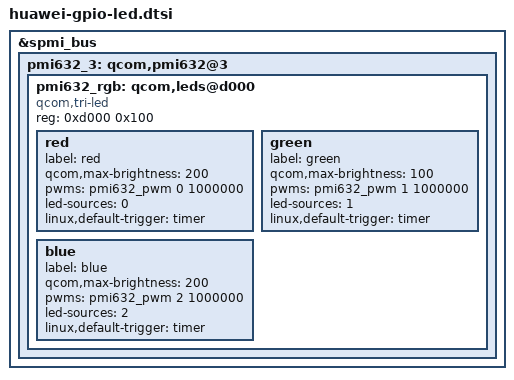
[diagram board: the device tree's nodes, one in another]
&spmi_bus {
	pmi632_3: qcom,pmi632@3 {
         pmi632_rgb: qcom,leds@d000 {
			compatible = "qcom,tri-led";
			reg = <0xd000 0x100>;
			red {
				label = "red";
				qcom,max-brightness = <200>;
				pwms = <&pmi632_pwm 0 1000000>;
				led-sources = <0>;
				linux,default-trigger = "timer";
			};
			green {
				label = "green";
				qcom,max-brightness = <100>;
				pwms = <&pmi632_pwm 1 1000000>;
				led-sources = <1>;
				linux,default-trigger = "timer";
			};
			blue {
				label = "blue";
				qcom,max-brightness = <200>;
				pwms = <&pmi632_pwm 2 1000000>;
				led-sources = <2>;
				linux,default-trigger = "timer";
			};
		};
	};
};	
